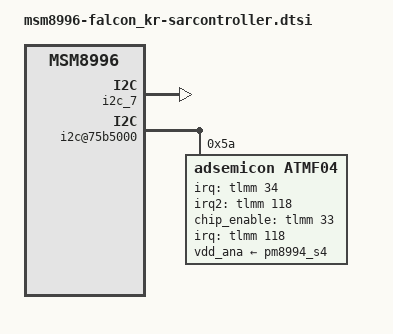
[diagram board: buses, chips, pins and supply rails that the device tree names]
/* Copyright (c) 2016, The Linux Foundation. All rights reserved.
 *
 * This program is free software; you can redistribute it and/or modify
 * it under the terms of the GNU General Public License version 2 and
 * only version 2 as published by the Free Software Foundation.
 *
 * This program is distributed in the hope that it will be useful,
 * but WITHOUT ANY WARRANTY; without even the implied warranty of
 * MERCHANTABILITY or FITNESS FOR A PARTICULAR PURPOSE.  See the
 * GNU General Public License for more details.
 */

&soc {
	i2c_7 {
		status = "ok";
	};

	i2c@75b5000 {
		qcom,clk-freq-out = <100000>;   // I2C writing issue for sar controller
		qcom,clk-freq-in  = <19200000>;

		atmf04@5a {
			compatible = "adsemicon,atmf04";
			status = "ok";
			reg = <0x5a>;

			interrupt-parent = <&tlmm>;
			interrupts = <118 0x2>;

			pinctrl-names = "default", "sleep";
			pinctrl-0 = <&atmf04_int_active>;
			pinctrl-1 = <&atmf04_int_suspend>;

			Adsemicon,vdd_ana-supply = <&pm8994_s4>;
			Adsemicon,irq-gpio = <&tlmm 34 0x00>;	/* Interrupt Pin */
			Adsemicon,irq2-gpio = <&tlmm 118 0x00>;	/* Interrupt Pin */
			Adsemicon,vdd_ana_supply_min = <1800000>;
			Adsemicon,vdd_ana_supply_max = <1800000>;
			Adsemicon,vdd_ana_load_ua = <15000>;
			Adsemicon,chip_enable = <&tlmm 33 0x00>;  /* enable pin */
			Adsemicon,InputPinsNum = <2>;
			Adsemicon,fw_name = "atmf04/atmf04_2CH_V0.41.fw";
		};
	};
};
